VERSION ""

NS_ :

BS_:

BU_: Controller Motor

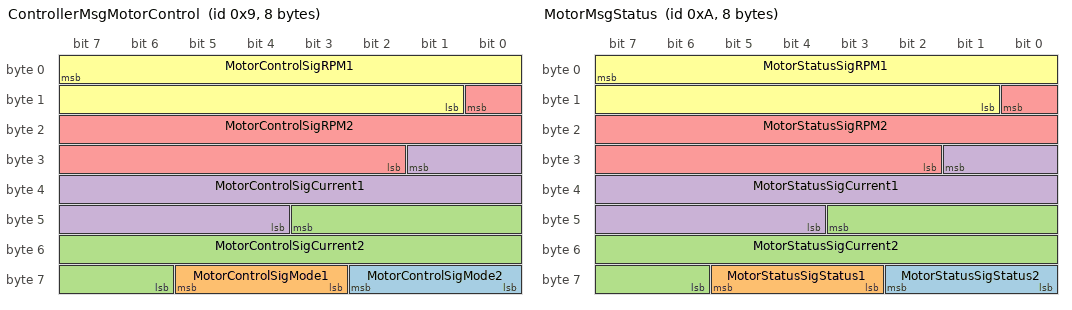
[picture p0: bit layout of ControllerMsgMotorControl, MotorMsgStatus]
BO_ 9 ControllerMsgMotorControl: 8 Controller
 SG_ MotorControlSigMode2 : 58|3@0+ (1,0) [0|3] ""  Motor
 SG_ MotorControlSigMode1 : 61|3@0+ (1,0) [0|3] ""  Motor
 SG_ MotorControlSigCurrent2 : 43|14@0- (1,0) [-6000|6000] "mA"  Motor
 SG_ MotorControlSigCurrent1 : 25|14@0- (1,0) [-6000|6000] "mA"  Motor
 SG_ MotorControlSigRPM2 : 8|15@0- (1,0) [-15000|15000] "RPM"  Motor
 SG_ MotorControlSigRPM1 : 7|15@0- (1,0) [-15000|15000] "RPM"  Motor

BO_ 10 MotorMsgStatus: 8 Motor
 SG_ MotorStatusSigStatus2 : 58|3@0+ (1,0) [0|3] ""  Controller
 SG_ MotorStatusSigStatus1 : 61|3@0+ (1,0) [0|3] ""  Controller
 SG_ MotorStatusSigCurrent2 : 43|14@0- (1,0) [-6000|6000] "mA"  Controller
 SG_ MotorStatusSigCurrent1 : 25|14@0- (1,0) [-6000|6000] "mA"  Controller
 SG_ MotorStatusSigRPM2 : 8|15@0- (1,0) [-15000|15000] "RPM"  Controller
 SG_ MotorStatusSigRPM1 : 7|15@0- (1,0) [-15000|15000] "RPM"  Controller

CM_ BU_ Controller "Node controlling the motor";
CM_ BU_ Motor "Node representing the motor";
CM_ BO_ 9 "Motor control message.";
CM_ SG_ 9 MotorControlSigMode2 "Mode for motor 2.";
CM_ SG_ 9 MotorControlSigMode1 "Mode for motor 1.";
CM_ SG_ 9 MotorControlSigCurrent2 "Max allowed current for motor 2.";
CM_ SG_ 9 MotorControlSigCurrent1 "Max allowed current for motor 1.";
CM_ SG_ 9 MotorControlSigRPM2 "Target RPM for motor 2.";
CM_ SG_ 9 MotorControlSigRPM1 "Target RPM for motor 1.";
CM_ BO_ 10 "Motor status message.";
CM_ SG_ 10 MotorStatusSigStatus2 "Actual mode for motor 2.";
CM_ SG_ 10 MotorStatusSigStatus1 "Actual mode for motor 1.";
CM_ SG_ 10 MotorStatusSigCurrent2 "Actual current for motor 2.";
CM_ SG_ 10 MotorStatusSigCurrent1 "Actual current for motor 1.";
CM_ SG_ 10 MotorStatusSigRPM2 "Actual RPM for motor 2.";
CM_ SG_ 10 MotorStatusSigRPM1 "Actual RPM for motor 1.";

VAL_ 9 MotorControlSigMode2 0 "UNKNOWN" 1 "RUN" 2 "COAST" 3 "BRAKE" ;
VAL_ 9 MotorControlSigMode1 0 "UNKNOWN" 1 "RUN" 2 "COAST" 3 "BRAKE" ;
VAL_ 10 MotorStatusSigStatus2 0 "UNKNOWN" 1 "RUN" 2 "COAST" 3 "BRAKE" 4 "SHORT_TO_GROUND" 5 "SHORT_TO_VCC" 6 "OPEN_LOAD" 7 "THERMAL_SHUTDOWN" ;
VAL_ 10 MotorStatusSigStatus1 0 "UNKNOWN" 1 "RUN" 2 "COAST" 3 "BRAKE" 4 "SHORT_TO_GROUND" 5 "SHORT_TO_VCC" 6 "OPEN_LOAD" 7 "THERMAL_SHUTDOWN" ;
